# A53SS0_CORE1_ECC_AGGR register map
Vendor: Texas Instruments
Peripheral module from a debugger description file (folder am62x).
Registers are 32-bit, access not given, reset 0x0 unless marked. A register's access mark holds for its fields unless they carry their own. Offsets are as the file gives them; lines under a group give offsets from that group; [hi:lo] are bit positions; {n}, {i} and the like mark numbered series; 'fields as' and 'values as' point back to an identical list; <NAME> marks a mode.

## A53SS0_CORE1_ECC_AGGR
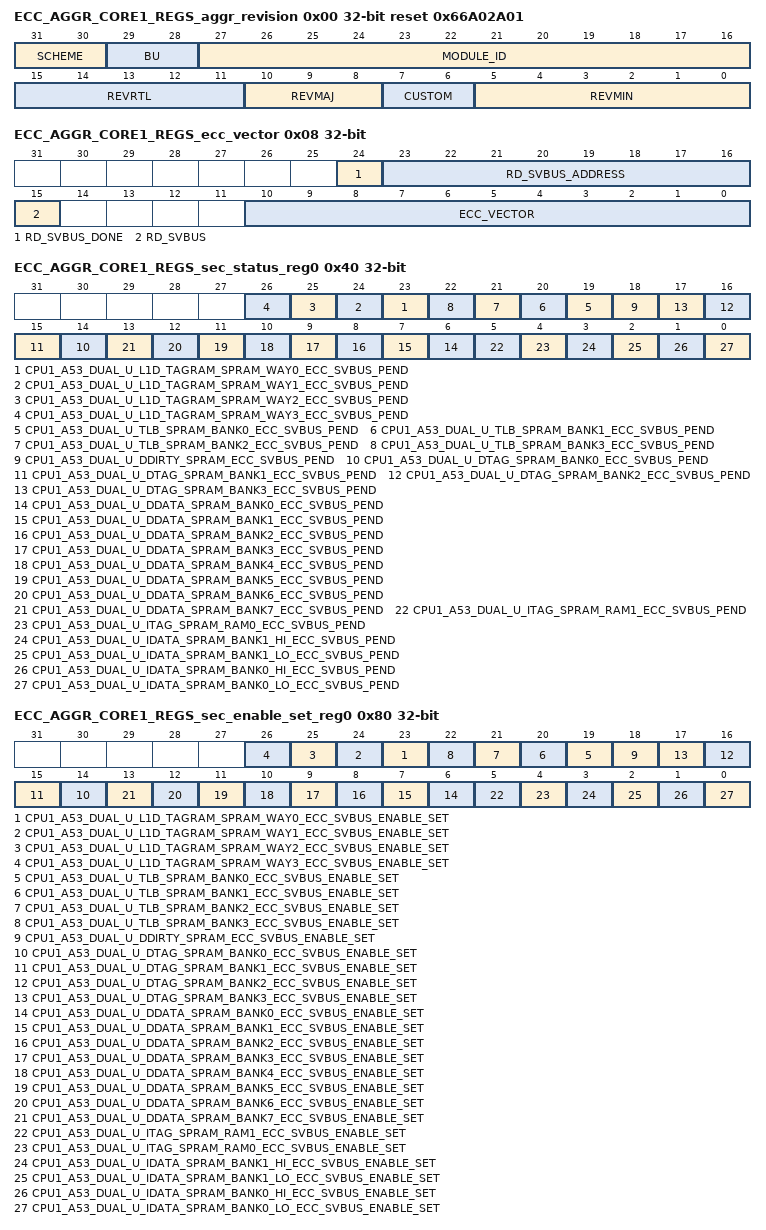
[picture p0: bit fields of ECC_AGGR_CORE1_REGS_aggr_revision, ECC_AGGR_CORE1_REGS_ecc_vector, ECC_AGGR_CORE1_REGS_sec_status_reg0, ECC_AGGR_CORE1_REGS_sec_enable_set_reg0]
0x00 ECC_AGGR_CORE1_REGS_aggr_revision ro reset 0x66A02A01 — Revision parameters
  [31:30] SCHEME
  [29:28] BU
  [27:16] MODULE_ID
  [15:11] REVRTL — RTL version
  [10:8] REVMAJ — Major version
  [7:6] CUSTOM — Custom version
  [5:0] REVMIN — Minor version
0x08 ECC_AGGR_CORE1_REGS_ecc_vector — ECC Vector Register
  [24] RD_SVBUS_DONE — Status to indicate if read on serial VBUS is complete, write of any value will clear this bit. (access R/W1TC)
  [23:16] RD_SVBUS_ADDRESS rw — Read address
  [15] RD_SVBUS — Write 1 to trigger a read on the serial VBUS (access R/W1TS)
  [10:0] ECC_VECTOR rw — Value written to select the corresponding ECC RAM for control or status
0x0C ECC_AGGR_CORE1_REGS_misc_status ro reset 0x1B — Misc Status
  [10:0] NUM_RAMS — Indicates the number of RAMS serviced by the ECC aggregator
0x10 ECC_AGGR_CORE1_REGS_reserved_svbus rw — Reference other documents that contain the ECC RAM wrapper and EDC controller serial vbus register sets.
  [31:0] DATA — Serial VBUS register data
0x3C ECC_AGGR_CORE1_REGS_sec_eoi_reg — EOI Register
  [0] EOI_WR — EOI Register (access R/W1TS)
0x40 ECC_AGGR_CORE1_REGS_sec_status_reg0 — Interrupt Status Register 0
  [n+23] CPU1_A53_DUAL_U_L1D_TAGRAM_SPRAM_WAY{n}_ECC_SVBUS_PEND (n=0..3) — Interrupt Pending Status for cpu1_a53_dual_u_l1d_tagram_spram_way{n}_ecc_svbus_pend (access R/W1TS)
  [n+19] CPU1_A53_DUAL_U_TLB_SPRAM_BANK{n}_ECC_SVBUS_PEND (n=0..3) — Interrupt Pending Status for cpu1_a53_dual_u_tlb_spram_bank{n}_ecc_svbus_pend (access R/W1TS)
  [18] CPU1_A53_DUAL_U_DDIRTY_SPRAM_ECC_SVBUS_PEND — Interrupt Pending Status for cpu1_a53_dual_u_ddirty_spram_ecc_svbus_pend (access R/W1TS)
  [n+14] CPU1_A53_DUAL_U_DTAG_SPRAM_BANK{n}_ECC_SVBUS_PEND (n=0..3) — Interrupt Pending Status for cpu1_a53_dual_u_dtag_spram_bank{n}_ecc_svbus_pend (access R/W1TS)
  [n+6] CPU1_A53_DUAL_U_DDATA_SPRAM_BANK{n}_ECC_SVBUS_PEND (n=0..7) — Interrupt Pending Status for cpu1_a53_dual_u_ddata_spram_bank{n}_ecc_svbus_pend (access R/W1TS)
  [5] CPU1_A53_DUAL_U_ITAG_SPRAM_RAM1_ECC_SVBUS_PEND — Interrupt Pending Status for cpu1_a53_dual_u_itag_spram_ram1_ecc_svbus_pend (access R/W1TS)
  [4] CPU1_A53_DUAL_U_ITAG_SPRAM_RAM0_ECC_SVBUS_PEND — Interrupt Pending Status for cpu1_a53_dual_u_itag_spram_ram0_ecc_svbus_pend (access R/W1TS)
  [3] CPU1_A53_DUAL_U_IDATA_SPRAM_BANK1_HI_ECC_SVBUS_PEND — Interrupt Pending Status for cpu1_a53_dual_u_idata_spram_bank1_hi_ecc_svbus_pend (access R/W1TS)
  [2] CPU1_A53_DUAL_U_IDATA_SPRAM_BANK1_LO_ECC_SVBUS_PEND — Interrupt Pending Status for cpu1_a53_dual_u_idata_spram_bank1_lo_ecc_svbus_pend (access R/W1TS)
  [1] CPU1_A53_DUAL_U_IDATA_SPRAM_BANK0_HI_ECC_SVBUS_PEND — Interrupt Pending Status for cpu1_a53_dual_u_idata_spram_bank0_hi_ecc_svbus_pend (access R/W1TS)
  [0] CPU1_A53_DUAL_U_IDATA_SPRAM_BANK0_LO_ECC_SVBUS_PEND — Interrupt Pending Status for cpu1_a53_dual_u_idata_spram_bank0_lo_ecc_svbus_pend (access R/W1TS)
0x80 ECC_AGGR_CORE1_REGS_sec_enable_set_reg0 — Interrupt Enable Set Register 0
  [n+23] CPU1_A53_DUAL_U_L1D_TAGRAM_SPRAM_WAY{n}_ECC_SVBUS_ENABLE_SET (n=0..3) — Interrupt Enable Set Register for cpu1_a53_dual_u_l1d_tagram_spram_way{n}_ecc_svbus_pend (access R/W1TS)
  [n+19] CPU1_A53_DUAL_U_TLB_SPRAM_BANK{n}_ECC_SVBUS_ENABLE_SET (n=0..3) — Interrupt Enable Set Register for cpu1_a53_dual_u_tlb_spram_bank{n}_ecc_svbus_pend (access R/W1TS)
  [18] CPU1_A53_DUAL_U_DDIRTY_SPRAM_ECC_SVBUS_ENABLE_SET — Interrupt Enable Set Register for cpu1_a53_dual_u_ddirty_spram_ecc_svbus_pend (access R/W1TS)
  [n+14] CPU1_A53_DUAL_U_DTAG_SPRAM_BANK{n}_ECC_SVBUS_ENABLE_SET (n=0..3) — Interrupt Enable Set Register for cpu1_a53_dual_u_dtag_spram_bank{n}_ecc_svbus_pend (access R/W1TS)
  [n+6] CPU1_A53_DUAL_U_DDATA_SPRAM_BANK{n}_ECC_SVBUS_ENABLE_SET (n=0..7) — Interrupt Enable Set Register for cpu1_a53_dual_u_ddata_spram_bank{n}_ecc_svbus_pend (access R/W1TS)
  [5] CPU1_A53_DUAL_U_ITAG_SPRAM_RAM1_ECC_SVBUS_ENABLE_SET — Interrupt Enable Set Register for cpu1_a53_dual_u_itag_spram_ram1_ecc_svbus_pend (access R/W1TS)
  [4] CPU1_A53_DUAL_U_ITAG_SPRAM_RAM0_ECC_SVBUS_ENABLE_SET — Interrupt Enable Set Register for cpu1_a53_dual_u_itag_spram_ram0_ecc_svbus_pend (access R/W1TS)
  [3] CPU1_A53_DUAL_U_IDATA_SPRAM_BANK1_HI_ECC_SVBUS_ENABLE_SET — Interrupt Enable Set Register for cpu1_a53_dual_u_idata_spram_bank1_hi_ecc_svbus_pend (access R/W1TS)
  [2] CPU1_A53_DUAL_U_IDATA_SPRAM_BANK1_LO_ECC_SVBUS_ENABLE_SET — Interrupt Enable Set Register for cpu1_a53_dual_u_idata_spram_bank1_lo_ecc_svbus_pend (access R/W1TS)
  [1] CPU1_A53_DUAL_U_IDATA_SPRAM_BANK0_HI_ECC_SVBUS_ENABLE_SET — Interrupt Enable Set Register for cpu1_a53_dual_u_idata_spram_bank0_hi_ecc_svbus_pend (access R/W1TS)
  [0] CPU1_A53_DUAL_U_IDATA_SPRAM_BANK0_LO_ECC_SVBUS_ENABLE_SET — Interrupt Enable Set Register for cpu1_a53_dual_u_idata_spram_bank0_lo_ecc_svbus_pend (access R/W1TS)
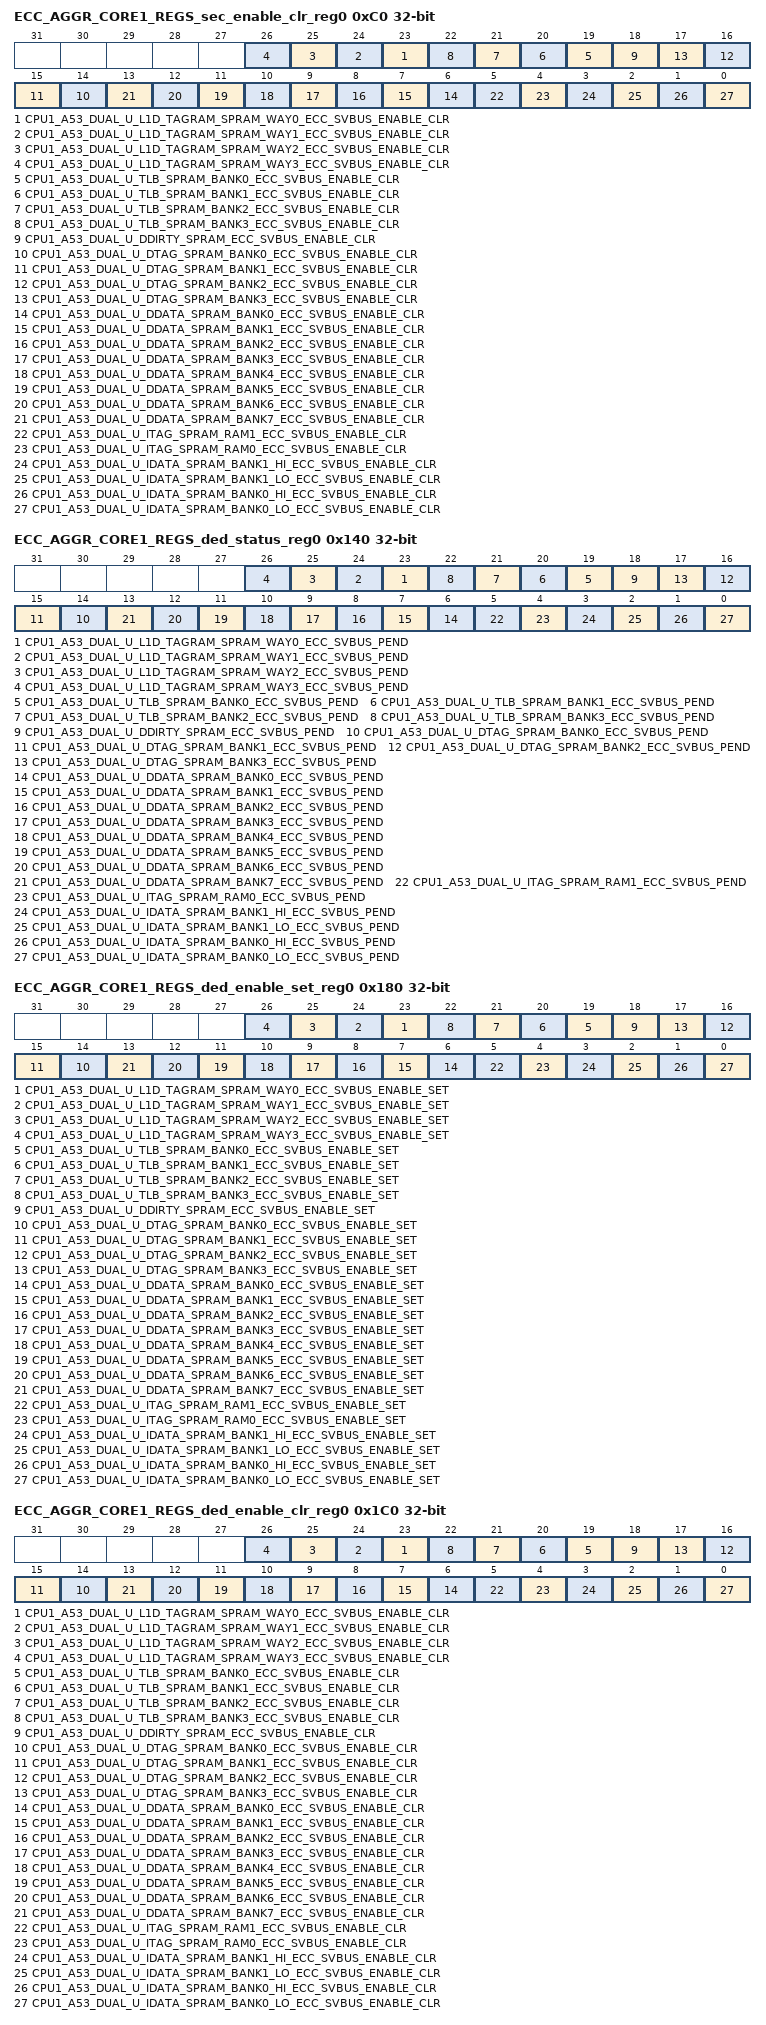
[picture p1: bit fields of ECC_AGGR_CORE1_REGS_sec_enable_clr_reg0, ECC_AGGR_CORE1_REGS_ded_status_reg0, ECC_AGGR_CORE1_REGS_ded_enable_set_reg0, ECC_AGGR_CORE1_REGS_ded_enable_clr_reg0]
0xC0 ECC_AGGR_CORE1_REGS_sec_enable_clr_reg0 — Interrupt Enable Clear Register 0
  [n+23] CPU1_A53_DUAL_U_L1D_TAGRAM_SPRAM_WAY{n}_ECC_SVBUS_ENABLE_CLR (n=0..3) — Interrupt Enable Clear Register for cpu1_a53_dual_u_l1d_tagram_spram_way{n}_ecc_svbus_pend (access R/W1TC)
  [n+19] CPU1_A53_DUAL_U_TLB_SPRAM_BANK{n}_ECC_SVBUS_ENABLE_CLR (n=0..3) — Interrupt Enable Clear Register for cpu1_a53_dual_u_tlb_spram_bank{n}_ecc_svbus_pend (access R/W1TC)
  [18] CPU1_A53_DUAL_U_DDIRTY_SPRAM_ECC_SVBUS_ENABLE_CLR — Interrupt Enable Clear Register for cpu1_a53_dual_u_ddirty_spram_ecc_svbus_pend (access R/W1TC)
  [n+14] CPU1_A53_DUAL_U_DTAG_SPRAM_BANK{n}_ECC_SVBUS_ENABLE_CLR (n=0..3) — Interrupt Enable Clear Register for cpu1_a53_dual_u_dtag_spram_bank{n}_ecc_svbus_pend (access R/W1TC)
  [n+6] CPU1_A53_DUAL_U_DDATA_SPRAM_BANK{n}_ECC_SVBUS_ENABLE_CLR (n=0..7) — Interrupt Enable Clear Register for cpu1_a53_dual_u_ddata_spram_bank{n}_ecc_svbus_pend (access R/W1TC)
  [5] CPU1_A53_DUAL_U_ITAG_SPRAM_RAM1_ECC_SVBUS_ENABLE_CLR — Interrupt Enable Clear Register for cpu1_a53_dual_u_itag_spram_ram1_ecc_svbus_pend (access R/W1TC)
  [4] CPU1_A53_DUAL_U_ITAG_SPRAM_RAM0_ECC_SVBUS_ENABLE_CLR — Interrupt Enable Clear Register for cpu1_a53_dual_u_itag_spram_ram0_ecc_svbus_pend (access R/W1TC)
  [3] CPU1_A53_DUAL_U_IDATA_SPRAM_BANK1_HI_ECC_SVBUS_ENABLE_CLR — Interrupt Enable Clear Register for cpu1_a53_dual_u_idata_spram_bank1_hi_ecc_svbus_pend (access R/W1TC)
  [2] CPU1_A53_DUAL_U_IDATA_SPRAM_BANK1_LO_ECC_SVBUS_ENABLE_CLR — Interrupt Enable Clear Register for cpu1_a53_dual_u_idata_spram_bank1_lo_ecc_svbus_pend (access R/W1TC)
  [1] CPU1_A53_DUAL_U_IDATA_SPRAM_BANK0_HI_ECC_SVBUS_ENABLE_CLR — Interrupt Enable Clear Register for cpu1_a53_dual_u_idata_spram_bank0_hi_ecc_svbus_pend (access R/W1TC)
  [0] CPU1_A53_DUAL_U_IDATA_SPRAM_BANK0_LO_ECC_SVBUS_ENABLE_CLR — Interrupt Enable Clear Register for cpu1_a53_dual_u_idata_spram_bank0_lo_ecc_svbus_pend (access R/W1TC)
0x13C ECC_AGGR_CORE1_REGS_ded_eoi_reg — EOI Register
  [0] EOI_WR — EOI Register (access R/W1TS)
0x140 ECC_AGGR_CORE1_REGS_ded_status_reg0 — Interrupt Status Register 0
  fields as ECC_AGGR_CORE1_REGS_sec_status_reg0
0x180 ECC_AGGR_CORE1_REGS_ded_enable_set_reg0 — Interrupt Enable Set Register 0
  fields as ECC_AGGR_CORE1_REGS_sec_enable_set_reg0
0x1C0 ECC_AGGR_CORE1_REGS_ded_enable_clr_reg0 — Interrupt Enable Clear Register 0
  fields as ECC_AGGR_CORE1_REGS_sec_enable_clr_reg0
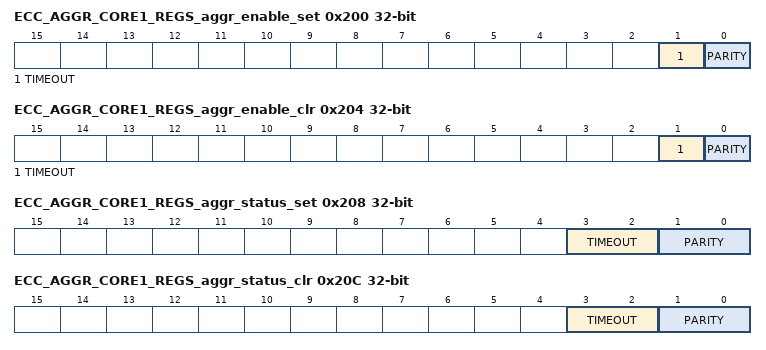
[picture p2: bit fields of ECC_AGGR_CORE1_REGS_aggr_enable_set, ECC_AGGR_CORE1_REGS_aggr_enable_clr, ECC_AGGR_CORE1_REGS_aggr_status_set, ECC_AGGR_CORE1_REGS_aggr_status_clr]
0x200 ECC_AGGR_CORE1_REGS_aggr_enable_set — AGGR interrupt enable set Register
  [1] TIMEOUT — interrupt enable set for svbus timeout errors (access R/W1TS)
  [0] PARITY — interrupt enable set for parity errors (access R/W1TS)
0x204 ECC_AGGR_CORE1_REGS_aggr_enable_clr — AGGR interrupt enable clear Register
  [1] TIMEOUT — interrupt enable clear for svbus timeout errors (access R/W1TC)
  [0] PARITY — interrupt enable clear for parity errors (access R/W1TC)
0x208 ECC_AGGR_CORE1_REGS_aggr_status_set — AGGR interrupt status set Register
  [3:2] TIMEOUT — interrupt status set for svbus timeout errors (access R/WI)
  [1:0] PARITY — interrupt status set for parity errors (access R/WI)
0x20C ECC_AGGR_CORE1_REGS_aggr_status_clr — AGGR interrupt status clear Register
  [3:2] TIMEOUT — interrupt status clear for svbus timeout errors (access R/WD)
  [1:0] PARITY — interrupt status clear for parity errors (access R/WD)
